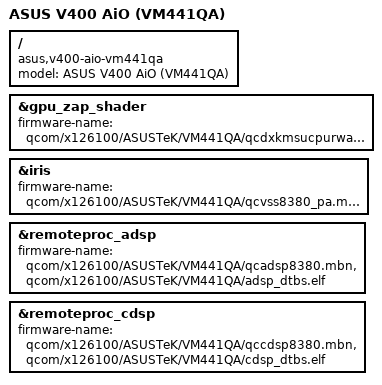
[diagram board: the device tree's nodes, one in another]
// SPDX-License-Identifier: BSD-3-Clause
/*
 * Copyright (c) 2026, Birk Skyum <birk.skyum@pm.me>
 */

/dts-v1/;

#include "x126100-asus-v400-aio.dtsi"

/ {
	model = "ASUS V400 AiO (VM441QA)";
	compatible = "asus,v400-aio-vm441qa", "qcom,x126100", "qcom,x1p42100";
};

&gpu_zap_shader {
	firmware-name = "qcom/x126100/ASUSTeK/VM441QA/qcdxkmsucpurwa.mbn";
};

&iris {
	firmware-name = "qcom/x126100/ASUSTeK/VM441QA/qcvss8380_pa.mbn";
};

&remoteproc_adsp {
	firmware-name = "qcom/x126100/ASUSTeK/VM441QA/qcadsp8380.mbn",
			"qcom/x126100/ASUSTeK/VM441QA/adsp_dtbs.elf";
};

&remoteproc_cdsp {
	firmware-name = "qcom/x126100/ASUSTeK/VM441QA/qccdsp8380.mbn",
			"qcom/x126100/ASUSTeK/VM441QA/cdsp_dtbs.elf";
};
